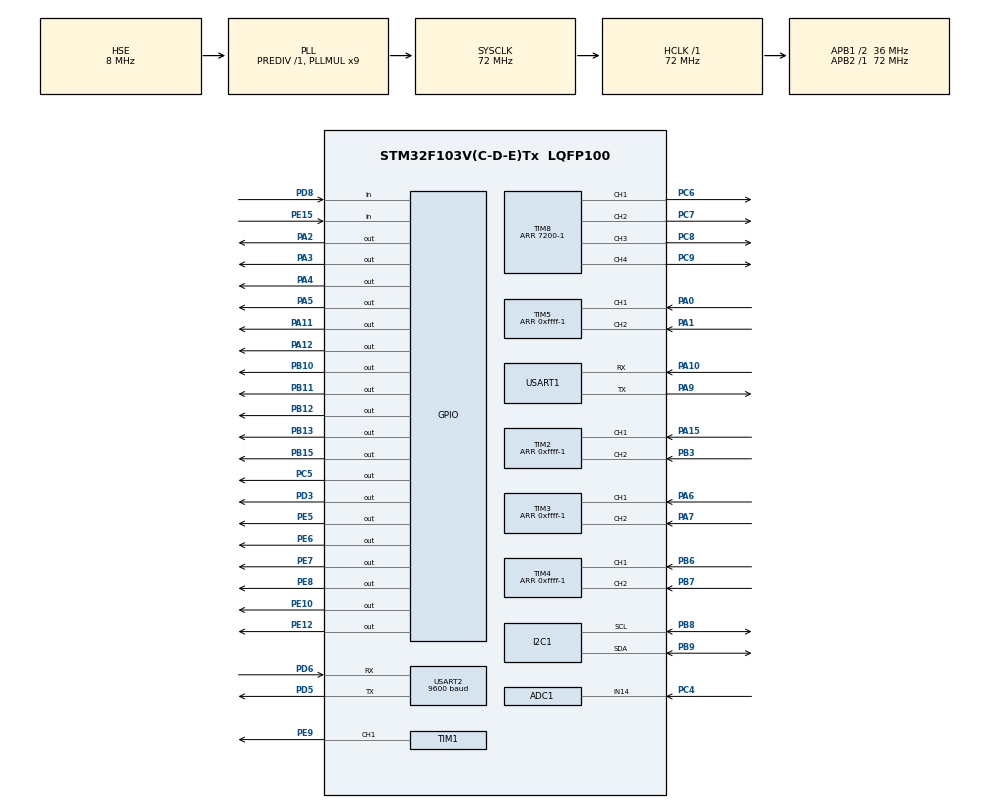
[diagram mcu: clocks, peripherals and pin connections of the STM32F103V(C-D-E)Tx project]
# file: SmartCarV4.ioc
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ADC1.Channel-0\#ChannelRegularConversion=ADC_CHANNEL_14
ADC1.ContinuousConvMode=ENABLE
ADC1.NbrOfConversionFlag=1
ADC1.Rank-0\#ChannelRegularConversion=1
ADC1.SamplingTime-0\#ChannelRegularConversion=ADC_SAMPLETIME_1CYCLE_5
ADC1.master=1
Dma.Request0=USART1_RX
Dma.Request1=USART1_TX
Dma.USART1_RX.0.Direction=DMA_PERIPH_TO_MEMORY
Dma.USART1_RX.0.Instance=DMA1_Channel5
Dma.USART1_RX.0.MemDataAlignment=DMA_MDATAALIGN_BYTE
Dma.USART1_RX.0.MemInc=DMA_MINC_ENABLE
Dma.USART1_RX.0.Mode=DMA_NORMAL
Dma.USART1_RX.0.PeriphDataAlignment=DMA_PDATAALIGN_BYTE
Dma.USART1_RX.0.PeriphInc=DMA_PINC_DISABLE
Dma.USART1_RX.0.Priority=DMA_PRIORITY_LOW
Dma.USART1_TX.1.Direction=DMA_MEMORY_TO_PERIPH
Dma.USART1_TX.1.Instance=DMA1_Channel4
Dma.USART1_TX.1.MemDataAlignment=DMA_MDATAALIGN_BYTE
Dma.USART1_TX.1.MemInc=DMA_MINC_ENABLE
Dma.USART1_TX.1.Mode=DMA_NORMAL
Dma.USART1_TX.1.PeriphDataAlignment=DMA_PDATAALIGN_BYTE
Dma.USART1_TX.1.PeriphInc=DMA_PINC_DISABLE
Dma.USART1_TX.1.Priority=DMA_PRIORITY_LOW
Mcu.Family=STM32F1
Mcu.Name=STM32F103V(C-D-E)Tx
Mcu.Package=LQFP100
NVIC.ADC1_2_IRQn=true\:0\:0\:false\:false\:true\:true\:true
NVIC.DMA1_Channel4_IRQn=true\:0\:0\:false\:false\:true\:false\:true
NVIC.DMA1_Channel5_IRQn=true\:0\:0\:false\:false\:true\:false\:true
NVIC.PriorityGroup=NVIC_PRIORITYGROUP_4
NVIC.USART1_IRQn=true\:0\:0\:false\:false\:true\:true\:true
NVIC.USART2_IRQn=true\:0\:0\:false\:false\:true\:true\:true
OSC_IN.Mode=HSE-External-Oscillator
OSC_IN.Signal=RCC_OSC_IN
OSC_OUT.Mode=HSE-External-Oscillator
OSC_OUT.Signal=RCC_OSC_OUT
PA0-WKUP.Signal=S_TIM5_CH1
PA1.Signal=S_TIM5_CH2
PA10.Mode=Asynchronous
PA10.Signal=USART1_RX
PA11.Signal=GPIO_Output
PA12.Signal=GPIO_Output
PA13.Mode=Serial_Wire
PA13.Signal=SYS_JTMS-SWDIO
PA14.Mode=Serial_Wire
PA14.Signal=SYS_JTCK-SWCLK
PA15.Signal=S_TIM2_CH1_ETR
PA2.Signal=GPIO_Output
PA3.Signal=GPIO_Output
PA4.Signal=GPIO_Output
PA5.Signal=GPIO_Output
PA6.Signal=S_TIM3_CH1
PA7.Signal=S_TIM3_CH2
PA9.Mode=Asynchronous
PA9.Signal=USART1_TX
PB10.Signal=GPIO_Output
PB11.Signal=GPIO_Output
PB12.Signal=GPIO_Output
PB13.Signal=GPIO_Output
PB15.Signal=GPIO_Output
PB3.Signal=S_TIM2_CH2
PB6.Signal=S_TIM4_CH1
PB7.Signal=S_TIM4_CH2
PB8.Mode=I2C
PB8.Signal=I2C1_SCL
PB9.Mode=I2C
PB9.Signal=I2C1_SDA
PC14-OSC32_IN.Mode=LSE-External-Oscillator
PC14-OSC32_IN.Signal=RCC_OSC32_IN
PC15-OSC32_OUT.Mode=LSE-External-Oscillator
PC15-OSC32_OUT.Signal=RCC_OSC32_OUT
PC4.Signal=ADCx_IN14
PC5.Signal=GPIO_Output
PC6.Signal=S_TIM8_CH1
PC7.Signal=S_TIM8_CH2
PC8.Signal=S_TIM8_CH3
PC9.Signal=S_TIM8_CH4
PD3.Signal=GPIO_Output
PD5.Mode=Asynchronous
PD5.Signal=USART2_TX
PD6.Mode=Asynchronous
PD6.Signal=USART2_RX
PD8.Signal=GPIO_Input
PE10.Signal=GPIO_Output
PE12.Signal=GPIO_Output
PE15.Signal=GPIO_Input
PE5.Signal=GPIO_Output
PE6.Signal=GPIO_Output
PE7.Signal=GPIO_Output
PE8.Signal=GPIO_Output
PE9.Signal=S_TIM1_CH1
ProjectManager.HeapSize=0x200
ProjectManager.StackSize=0x400
ProjectManager.TargetToolchain=SW4STM32
RCC.ADCPresc=RCC_ADCPCLK2_DIV6
RCC.AHBFreq_Value=72000000
RCC.APB1CLKDivider=RCC_HCLK_DIV2
RCC.APB1Freq_Value=36000000
RCC.APB1TimFreq_Value=72000000
RCC.APB2Freq_Value=72000000
RCC.APB2TimFreq_Value=72000000
RCC.HCLKFreq_Value=72000000
RCC.PLLMUL=RCC_PLL_MUL9
RCC.PLLSourceVirtual=RCC_PLLSOURCE_HSE
RCC.SYSCLKFreq_VALUE=72000000
RCC.SYSCLKSource=RCC_SYSCLKSOURCE_PLLCLK
RCC.USBFreq_Value=72000000
SH.ADCx_IN14.0=ADC1_IN14,IN14
SH.S_TIM1_CH1.0=TIM1_CH1,PWM Generation1 CH1
SH.S_TIM2_CH1_ETR.0=TIM2_CH1,Encoder_Interface
SH.S_TIM2_CH2.0=TIM2_CH2,Encoder_Interface
SH.S_TIM3_CH1.0=TIM3_CH1,Encoder_Interface
SH.S_TIM3_CH2.0=TIM3_CH2,Encoder_Interface
SH.S_TIM4_CH1.0=TIM4_CH1,Encoder_Interface
SH.S_TIM4_CH2.0=TIM4_CH2,Encoder_Interface
SH.S_TIM5_CH1.0=TIM5_CH1,Encoder_Interface
SH.S_TIM5_CH2.0=TIM5_CH2,Encoder_Interface
SH.S_TIM8_CH1.0=TIM8_CH1,PWM Generation1 CH1
SH.S_TIM8_CH2.0=TIM8_CH2,PWM Generation2 CH2
SH.S_TIM8_CH3.0=TIM8_CH3,PWM Generation3 CH3
SH.S_TIM8_CH4.0=TIM8_CH4,PWM Generation4 CH4
TIM1.AutoReloadPreload=TIM_AUTORELOAD_PRELOAD_ENABLE
TIM1.Channel-PWM\ Generation1\ CH1=TIM_CHANNEL_1
TIM1.Period=20000-1
TIM1.Prescaler=72-1
TIM2.AutoReloadPreload=TIM_AUTORELOAD_PRELOAD_ENABLE
TIM2.EncoderMode=TIM_ENCODERMODE_TI12
TIM2.Period=0xffff-1
TIM3.AutoReloadPreload=TIM_AUTORELOAD_PRELOAD_ENABLE
TIM3.EncoderMode=TIM_ENCODERMODE_TI12
TIM3.Period=0xffff-1
TIM4.AutoReloadPreload=TIM_AUTORELOAD_PRELOAD_ENABLE
TIM4.EncoderMode=TIM_ENCODERMODE_TI12
TIM4.Period=0xffff-1
TIM5.AutoReloadPreload=TIM_AUTORELOAD_PRELOAD_ENABLE
TIM5.EncoderMode=TIM_ENCODERMODE_TI12
TIM5.Period=0xffff-1
TIM6.AutoReloadPreload=TIM_AUTORELOAD_PRELOAD_ENABLE
TIM6.Period=0xffff
TIM6.Prescaler=72-1
TIM8.AutoReloadPreload=TIM_AUTORELOAD_PRELOAD_ENABLE
TIM8.Channel-PWM\ Generation1\ CH1=TIM_CHANNEL_1
TIM8.Channel-PWM\ Generation2\ CH2=TIM_CHANNEL_2
TIM8.Channel-PWM\ Generation3\ CH3=TIM_CHANNEL_3
TIM8.Channel-PWM\ Generation4\ CH4=TIM_CHANNEL_4
TIM8.OCIdleState_1=TIM_OCIDLESTATE_RESET
TIM8.OCIdleState_2=TIM_OCIDLESTATE_RESET
TIM8.OCIdleState_3=TIM_OCIDLESTATE_RESET
TIM8.OCIdleState_4=TIM_OCIDLESTATE_RESET
TIM8.Period=7200-1
USART1.VirtualMode=VM_ASYNC
USART2.BaudRate=9600
USART2.VirtualMode=VM_ASYNC
VP_TIM6_VS_ClockSourceINT.Mode=Enable_Timer
board=custom

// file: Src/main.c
/* USER CODE BEGIN Header */
/**
  ******************************************************************************
  * @file           : main.c
  * @brief          : Main program body
  ******************************************************************************
  * @attention
  *
  * <h2><center>&copy; Copyright (c) 2021 STMicroelectronics.
  * All rights reserved.</center></h2>
  *
  * This software component is licensed by ST under BSD 3-Clause license,
  * the "License"; You may not use this file except in compliance with the
  * License. You may obtain a copy of the License at:
  *                        opensource.org/licenses/BSD-3-Clause
  *
  ******************************************************************************
  */
/* USER CODE END Header */

#include "main.h"
#include "adc.h"
#include "dma.h"
#include "i2c.h"
#include "tim.h"
#include "usart.h"
#include "gpio.h"

/* USER CODE BEGIN Includes */
/*********************** printf ***********************/

#ifdef __GNUC__
#define PUTCHAR_PROTOTYPE int __io_putchar(int ch)
#else
#define PUTCHAR_PROTOTYPE int fputc(int ch, FILE *f)
#endif

PUTCHAR_PROTOTYPE {
    HAL_UART_Transmit(&huart1, (uint8_t *) &ch, 1, 0xffff);
    return ch;
}
/************************ printf  **********************/

#include "smartcar/robot.h"
/* USER CODE END Includes */

void SystemClock_Config(void);

int main(void)
{

  /* MCU Configuration--------------------------------------------------------*/

  /* Reset of all peripherals, Initializes the Flash interface and the Systick. */
  HAL_Init();

  /* Configure the system clock */
  SystemClock_Config();

  /* Initialize all configured peripherals */
  MX_GPIO_Init();
  MX_DMA_Init();
  MX_USART1_UART_Init();
  MX_TIM8_Init();
  MX_TIM1_Init();
  MX_TIM2_Init();
  MX_TIM6_Init();
  MX_USART2_UART_Init();
  MX_I2C1_Init();
  MX_ADC1_Init();
  MX_TIM3_Init();
  MX_TIM4_Init();
  MX_TIM5_Init();

  /* Infinite loop */
  /* USER CODE BEGIN WHILE */
    /*** 初始化机器人 ***/
    SmartcarRobotInit();

    while (1) {

        SmartcarRobotTick();
    /* USER CODE END WHILE */

    }
}

void SystemClock_Config(void)
{
  RCC_OscInitTypeDef RCC_OscInitStruct = {0};
  RCC_ClkInitTypeDef RCC_ClkInitStruct = {0};
  RCC_PeriphCLKInitTypeDef PeriphClkInit = {0};

  /** Initializes the CPU, AHB and APB busses clocks
  */
  RCC_OscInitStruct.OscillatorType = RCC_OSCILLATORTYPE_HSE;
  RCC_OscInitStruct.HSEState = RCC_HSE_ON;
  RCC_OscInitStruct.HSEPredivValue = RCC_HSE_PREDIV_DIV1;
  RCC_OscInitStruct.HSIState = RCC_HSI_ON;
  RCC_OscInitStruct.PLL.PLLState = RCC_PLL_ON;
  RCC_OscInitStruct.PLL.PLLSource = RCC_PLLSOURCE_HSE;
  RCC_OscInitStruct.PLL.PLLMUL = RCC_PLL_MUL9;
  if (HAL_RCC_OscConfig(&RCC_OscInitStruct) != HAL_OK)
  {
    Error_Handler();
  }
  /** Initializes the CPU, AHB and APB busses clocks
  */
  RCC_ClkInitStruct.ClockType = RCC_CLOCKTYPE_HCLK|RCC_CLOCKTYPE_SYSCLK
                              |RCC_CLOCKTYPE_PCLK1|RCC_CLOCKTYPE_PCLK2;
  RCC_ClkInitStruct.SYSCLKSource = RCC_SYSCLKSOURCE_PLLCLK;
  RCC_ClkInitStruct.AHBCLKDivider = RCC_SYSCLK_DIV1;
  RCC_ClkInitStruct.APB1CLKDivider = RCC_HCLK_DIV2;
  RCC_ClkInitStruct.APB2CLKDivider = RCC_HCLK_DIV1;

  if (HAL_RCC_ClockConfig(&RCC_ClkInitStruct, FLASH_LATENCY_2) != HAL_OK)
  {
    Error_Handler();
  }
  PeriphClkInit.PeriphClockSelection = RCC_PERIPHCLK_ADC;
  PeriphClkInit.AdcClockSelection = RCC_ADCPCLK2_DIV6;
  if (HAL_RCCEx_PeriphCLKConfig(&PeriphClkInit) != HAL_OK)
  {
    Error_Handler();
  }
}

void Error_Handler(void)
{
}

/************************ (C) COPYRIGHT STMicroelectronics *****END OF FILE****/
